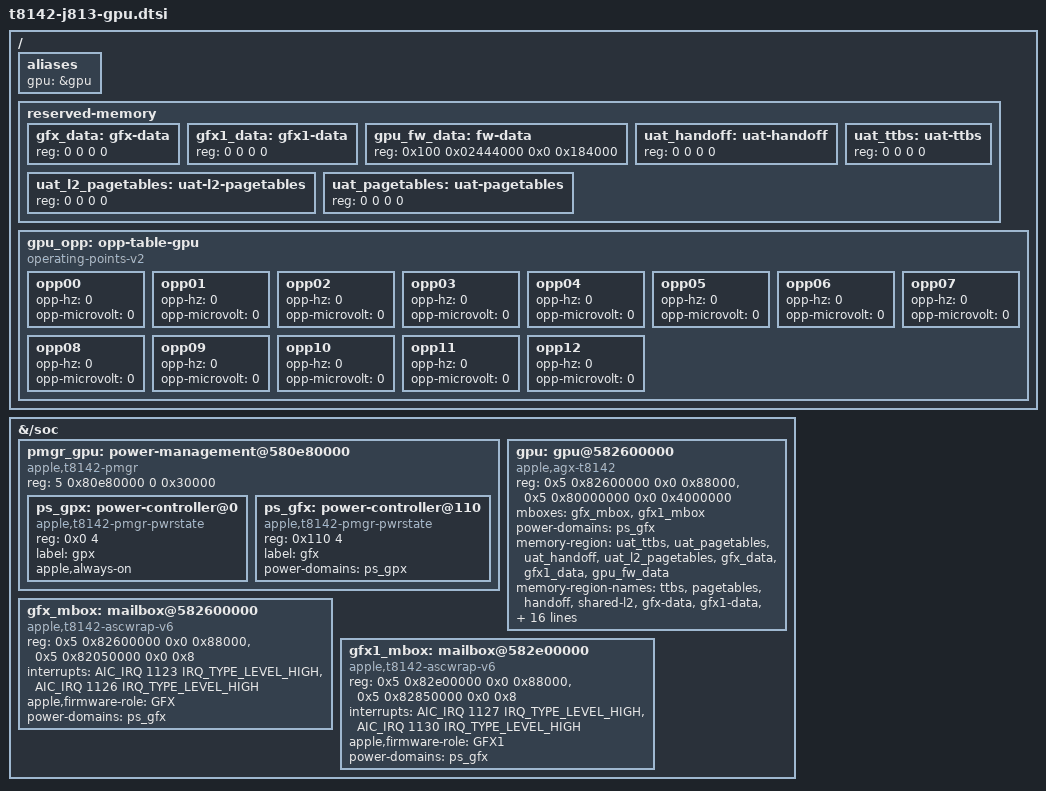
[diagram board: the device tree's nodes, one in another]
// SPDX-License-Identifier: GPL-2.0+ OR MIT
/*
 * M5 (T8142) GPU, laid out like the A18 Pro's (t8140.dtsi). Addresses and
 * interrupts are from the J813 ADT (sgx, gfx-asc, gfx1-asc, pmgr reg[48]).
 * The bootloader fills the uat-* regions from iBoot's raw-boot handoff, the
 * gfx-data regions from the firmware DATA segments iBoot loaded, and the
 * OPPs from sgx perf-states.
 */

/ {
	aliases {
		gpu = &gpu;
	};

	reserved-memory {
		/* gfx-asc and gfx1-asc __DATA (ADT sgx gfx-data, gfx1-data) */
		gfx_data: gfx-data {
			reg = <0 0 0 0>;
		};

		gfx1_data: gfx1-data {
			reg = <0 0 0 0>;
		};

		/*
		 * macOS 27.0 (26A428): both roles' __DATA and __DATA_SHARED_RO, contiguous
		 * (ADT gfx-asc and gfx1-asc segment-ranges), where the firmware places its crash
		 * logs. Fixed at the addresses iBoot has used on every 27.0 boot so far, until the
		 * bootloader fills it in.
		 */
		/* Mapped like gfx-data: the driver reads the crash logs through the linear map. */
		gpu_fw_data: fw-data {
			reg = <0x100 0x02444000 0x0 0x184000>;
		};

		uat_handoff: uat-handoff {
			reg = <0 0 0 0>;
		};

		uat_l2_pagetables: uat-l2-pagetables {
			reg = <0 0 0 0>;
		};

		uat_pagetables: uat-pagetables {
			reg = <0 0 0 0>;
		};

		uat_ttbs: uat-ttbs {
			reg = <0 0 0 0>;
		};
	};

	gpu_opp: opp-table-gpu {
		compatible = "operating-points-v2";

		/* 13 entries in perf-state order, filled in by the bootloader */
		opp00 { opp-hz = /bits/ 64 <0>; opp-microvolt = <0>; };
		opp01 { opp-hz = /bits/ 64 <0>; opp-microvolt = <0>; };
		opp02 { opp-hz = /bits/ 64 <0>; opp-microvolt = <0>; };
		opp03 { opp-hz = /bits/ 64 <0>; opp-microvolt = <0>; };
		opp04 { opp-hz = /bits/ 64 <0>; opp-microvolt = <0>; };
		opp05 { opp-hz = /bits/ 64 <0>; opp-microvolt = <0>; };
		opp06 { opp-hz = /bits/ 64 <0>; opp-microvolt = <0>; };
		opp07 { opp-hz = /bits/ 64 <0>; opp-microvolt = <0>; };
		opp08 { opp-hz = /bits/ 64 <0>; opp-microvolt = <0>; };
		opp09 { opp-hz = /bits/ 64 <0>; opp-microvolt = <0>; };
		opp10 { opp-hz = /bits/ 64 <0>; opp-microvolt = <0>; };
		opp11 { opp-hz = /bits/ 64 <0>; opp-microvolt = <0>; };
		opp12 { opp-hz = /bits/ 64 <0>; opp-microvolt = <0>; };
	};
};

&{/soc} {
	pmgr_gpu: power-management@580e80000 {
		compatible = "apple,t8142-pmgr", "apple,t8103-pmgr", "syscon", "simple-mfd";
		reg = <5 0x80e80000 0 0x30000>;
		#address-cells = <1>;
		#size-cells = <1>;

		ps_gpx: power-controller@0 {
			compatible = "apple,t8142-pmgr-pwrstate", "apple,t8103-pmgr-pwrstate";
			reg = <0x0 4>;
			#power-domain-cells = <0>;
			#reset-cells = <0>;
			label = "gpx";
			apple,always-on; /* critical */
		};

		ps_gfx: power-controller@110 {
			compatible = "apple,t8142-pmgr-pwrstate", "apple,t8103-pmgr-pwrstate";
			reg = <0x110 4>;
			#power-domain-cells = <0>;
			#reset-cells = <0>;
			label = "gfx";
			power-domains = <&ps_gpx>;
		};
	};

	gpu: gpu@582600000 {
		compatible = "apple,agx-t8142";
		reg = <0x5 0x82600000 0x0 0x88000>,
		      <0x5 0x80000000 0x0 0x4000000>;
		reg-names = "asc", "sgx";
		mboxes = <&gfx_mbox>, <&gfx1_mbox>;
		power-domains = <&ps_gfx>;
		memory-region = <&uat_ttbs>, <&uat_pagetables>, <&uat_handoff>,
				<&uat_l2_pagetables>, <&gfx_data>, <&gfx1_data>,
				<&gpu_fw_data>;
		memory-region-names = "ttbs", "pagetables", "handoff",
				      "shared-l2", "gfx-data", "gfx1-data", "fw-data";
		operating-points-v2 = <&gpu_opp>;
		/* Holds the DCS and fabric floor while GPU work is in flight. */
		apple,clpc = <&clpc>;

		/*
		 * The board's GPU power data, which the driver requires (J813 and J815, which
		 * runs the J813's). SRAM voltage per OPP: the J813 ADT's sgx perf-states-sram.
		 */
		apple,sram-microvolt = <770000 770000 770000 770000 770000 770000 770000
					790000 830000 865000 890000 945000 1010000>;
		/*
		 * Relative performance per OPP (IEEE single, percent), from macOS 27.0's own
		 * hardware data on a J813 (bundle +0x19e4): 19.4 % at the lowest state up to 100.
		 */
		apple,m5-relative-power = <0 0x419b36eb 0x41d06202 0x4205907a 0x42274b32
					   0x4247eae1 0x426b0873 0x428a5bac 0x42a45b3f
					   0x42ab4981 0x42b03cd5 0x42bb20f3 0x42c80000>;
		/* AON row RT0g (index 0x1d), as the J813's 25G76 AON block carries it. */
		apple,m5-aon-records = <0x67305452 0x001d0001 0x00001401>;
		/*
		 * Words of macOS 27.0's own hardware data on the J813, read out of its bundle,
		 * that the driver's template leaves different.
		 */
		apple,m5-hw-words = <0x0fa8 0x8000>, <0x0fb4 2>, <0x0fb8 0>, <0x1044 0xc>,
				    <0x10a4 0xa>, <0x10d4 0x17>, <0x1118 0>, <0x2660 4>,
				    <0x2720 1>, <0x2724 0>;
		/* Region C and the power policy are the driver's template as they are. */
		apple,m5-region-c-words = <>;
		apple,m5-policy-words = <>;
		apple,idleoff-standby-timer = <1250>;
	};

	gfx_mbox: mailbox@582600000 {
		compatible = "apple,t8142-ascwrap-v6";
		reg = <0x5 0x82600000 0x0 0x88000>,
		      <0x5 0x82050000 0x0 0x8>;
		reg-names = "wrapper", "iop-vbar";
		interrupts = <AIC_IRQ 1123 IRQ_TYPE_LEVEL_HIGH>,
			     <AIC_IRQ 1126 IRQ_TYPE_LEVEL_HIGH>;
		interrupt-names = "send-empty", "recv-not-empty";
		apple,firmware-role = "GFX";
		power-domains = <&ps_gfx>;
		#mbox-cells = <0>;
	};

	gfx1_mbox: mailbox@582e00000 {
		compatible = "apple,t8142-ascwrap-v6";
		reg = <0x5 0x82e00000 0x0 0x88000>,
		      <0x5 0x82850000 0x0 0x8>;
		reg-names = "wrapper", "iop-vbar";
		interrupts = <AIC_IRQ 1127 IRQ_TYPE_LEVEL_HIGH>,
			     <AIC_IRQ 1130 IRQ_TYPE_LEVEL_HIGH>;
		interrupt-names = "send-empty", "recv-not-empty";
		apple,firmware-role = "GFX1";
		power-domains = <&ps_gfx>;
		#mbox-cells = <0>;
	};
};
